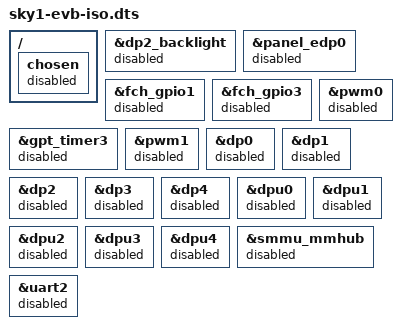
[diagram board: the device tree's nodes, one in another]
/*
 * Copyright 2024 Cix Technology Group Co., Ltd.
 *
 * SPDX-License-Identifier: BSD-3-Clause
 */

/dts-v1/;
#include "sky1-evb.dts"
/ {
	chosen {
		status = "disabled";
	};
};

&dp2_backlight {
	status = "disabled";
};

&panel_edp0 {
	status = "disabled";
};

&fch_gpio1 {
	status = "disabled";
};

&fch_gpio3 {
	status = "disabled";
};

&gpt_timer3 {
	status = "disabled";
};

&pwm0 {
	status = "disabled";
};

&pwm1 {
	status = "disabled";
};

&dp0 {
	status = "disabled";
};

&dp1 {
	status = "disabled";
};

&dp2 {
	status = "disabled";
};

&dp3 {
	status = "disabled";
};

&dp4 {
	status = "disabled";
};

&dpu0 {
	status = "disabled";
};

&dpu1 {
	status = "disabled";
};

&dpu2 {
	status = "disabled";
};

&dpu3 {
	status = "disabled";
};

&dpu4 {
	status = "disabled";
};

&smmu_mmhub{
	status = "disabled";
};

&uart2 {
	status = "disabled";
};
